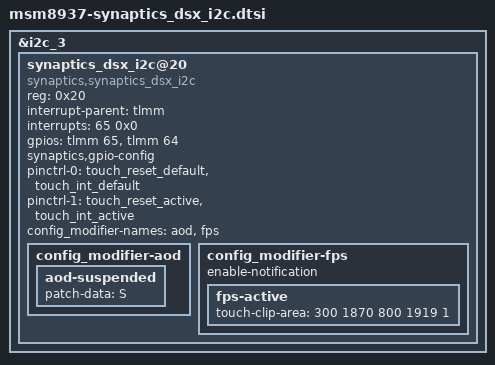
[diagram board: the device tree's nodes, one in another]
&i2c_3 {
	synaptics_dsx_i2c@20 {
		compatible = "synaptics,synaptics_dsx_i2c";
		reg = <0x20>;
		interrupt-parent = <&tlmm>;
		interrupts = <65 0x0>;
		gpios = <&tlmm 65 0x0>, /* IRQ */
			<&tlmm 64 0>; /* RESET */
		synaptics,gpio-config;
		pinctrl-names = "default", "active";
		pinctrl-0 = <&touch_reset_default &touch_int_default>;
		pinctrl-1 = <&touch_reset_active &touch_int_active>;
		config_modifier-names = "aod", "fps";
		config_modifier-aod {
			aod-suspended {
				/* Power->sleep; */
				patch-data = "S";
			};
		};
		config_modifier-fps {
			enable-notification;
			fps-active {
				touch-clip-area = <300 1870 800 1919 1>;
			};
		};
	};
};
